VERSION ""

NS_ :

BS_:

BU_: XXX

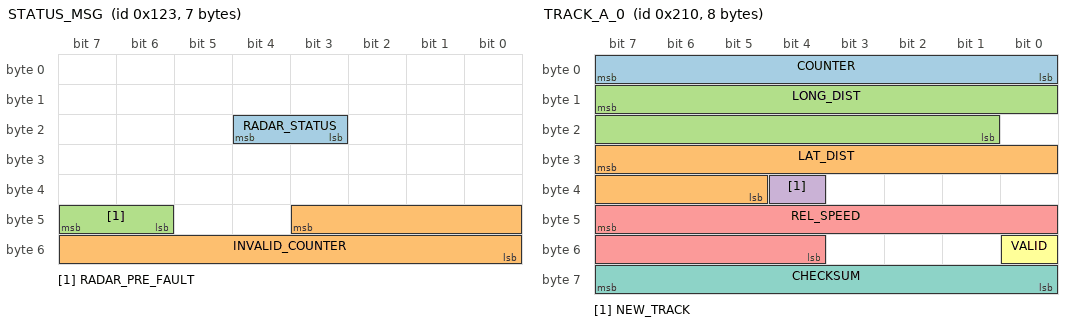
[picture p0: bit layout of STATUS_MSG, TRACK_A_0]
BO_ 291 STATUS_MSG: 7 XXX
 SG_ RADAR_STATUS : 20|2@0+ (1,0) [0|3] "" XXX
 SG_ INVALID_COUNTER : 43|12@0+ (1,0) [0|4095] "" XXX
 SG_ RADAR_PRE_FAULT : 47|2@0+ (1,0) [0|3] "" XXX

BO_ 528 TRACK_A_0: 8 XXX
 SG_ COUNTER : 7|8@0+ (1,0) [0|255] "" XXX
 SG_ LAT_DIST : 31|11@0- (0.04,0) [-50|50] "m" XXX
 SG_ LONG_DIST : 15|15@0+ (0.01,0) [0|300] "m" XXX
 SG_ NEW_TRACK : 36|1@0+ (1,0) [0|1] "" XXX
 SG_ REL_SPEED : 47|12@0- (0.025,0) [-100|100] "m/s" XXX
 SG_ VALID : 48|1@0+ (1,0) [0|1] "" XXX
 SG_ CHECKSUM : 63|8@0+ (1,0) [0|255] "" XXX

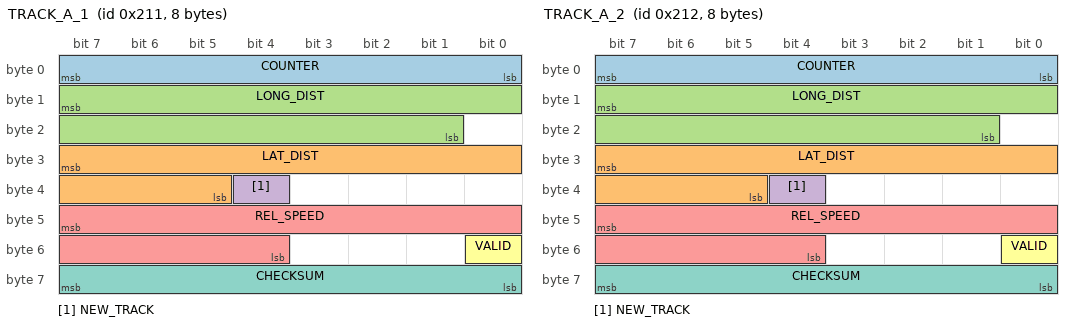
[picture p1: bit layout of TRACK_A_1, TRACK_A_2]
BO_ 529 TRACK_A_1: 8 XXX
 SG_ COUNTER : 7|8@0+ (1,0) [0|255] "" XXX
 SG_ LAT_DIST : 31|11@0- (0.04,0) [-50|50] "m" XXX
 SG_ LONG_DIST : 15|15@0+ (0.01,0) [0|300] "m" XXX
 SG_ NEW_TRACK : 36|1@0+ (1,0) [0|1] "" XXX
 SG_ REL_SPEED : 47|12@0- (0.025,0) [-100|100] "m/s" XXX
 SG_ VALID : 48|1@0+ (1,0) [0|1] "" XXX
 SG_ CHECKSUM : 63|8@0+ (1,0) [0|255] "" XXX

BO_ 530 TRACK_A_2: 8 XXX
 SG_ COUNTER : 7|8@0+ (1,0) [0|255] "" XXX
 SG_ LAT_DIST : 31|11@0- (0.04,0) [-50|50] "m" XXX
 SG_ LONG_DIST : 15|15@0+ (0.01,0) [0|300] "m" XXX
 SG_ NEW_TRACK : 36|1@0+ (1,0) [0|1] "" XXX
 SG_ REL_SPEED : 47|12@0- (0.025,0) [-100|100] "m/s" XXX
 SG_ VALID : 48|1@0+ (1,0) [0|1] "" XXX
 SG_ CHECKSUM : 63|8@0+ (1,0) [0|255] "" XXX

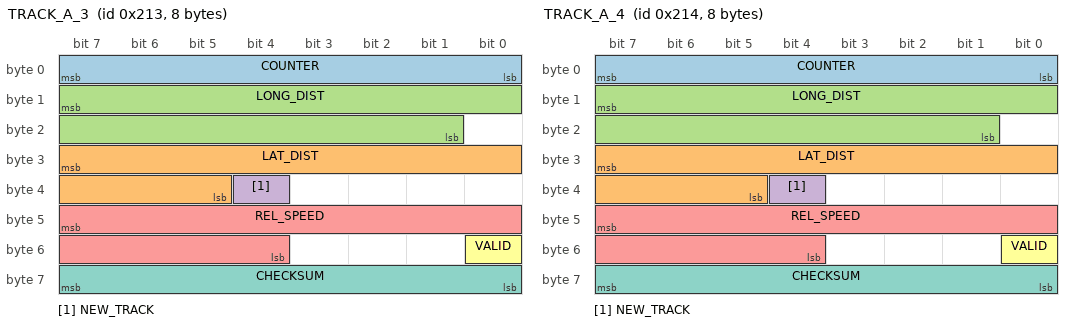
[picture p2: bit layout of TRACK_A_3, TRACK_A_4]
BO_ 531 TRACK_A_3: 8 XXX
 SG_ COUNTER : 7|8@0+ (1,0) [0|255] "" XXX
 SG_ LAT_DIST : 31|11@0- (0.04,0) [-50|50] "m" XXX
 SG_ LONG_DIST : 15|15@0+ (0.01,0) [0|300] "m" XXX
 SG_ NEW_TRACK : 36|1@0+ (1,0) [0|1] "" XXX
 SG_ REL_SPEED : 47|12@0- (0.025,0) [-100|100] "m/s" XXX
 SG_ VALID : 48|1@0+ (1,0) [0|1] "" XXX
 SG_ CHECKSUM : 63|8@0+ (1,0) [0|255] "" XXX

BO_ 532 TRACK_A_4: 8 XXX
 SG_ COUNTER : 7|8@0+ (1,0) [0|255] "" XXX
 SG_ LAT_DIST : 31|11@0- (0.04,0) [-50|50] "m" XXX
 SG_ LONG_DIST : 15|15@0+ (0.01,0) [0|300] "m" XXX
 SG_ NEW_TRACK : 36|1@0+ (1,0) [0|1] "" XXX
 SG_ REL_SPEED : 47|12@0- (0.025,0) [-100|100] "m/s" XXX
 SG_ VALID : 48|1@0+ (1,0) [0|1] "" XXX
 SG_ CHECKSUM : 63|8@0+ (1,0) [0|255] "" XXX

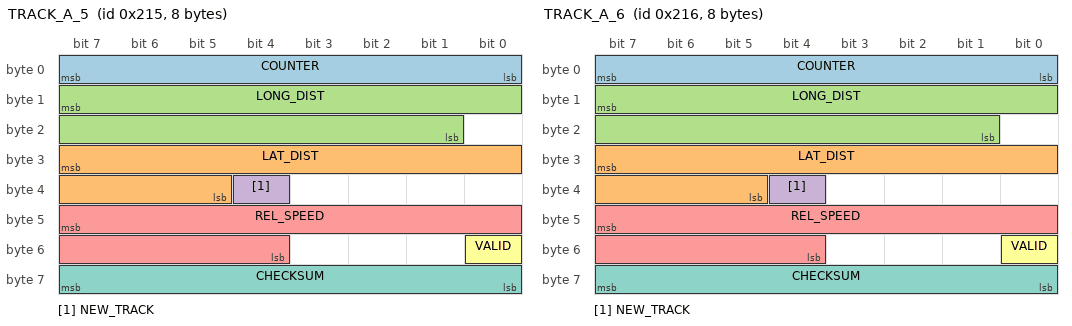
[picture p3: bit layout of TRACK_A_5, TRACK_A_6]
BO_ 533 TRACK_A_5: 8 XXX
 SG_ COUNTER : 7|8@0+ (1,0) [0|255] "" XXX
 SG_ LAT_DIST : 31|11@0- (0.04,0) [-50|50] "m" XXX
 SG_ LONG_DIST : 15|15@0+ (0.01,0) [0|300] "m" XXX
 SG_ NEW_TRACK : 36|1@0+ (1,0) [0|1] "" XXX
 SG_ REL_SPEED : 47|12@0- (0.025,0) [-100|100] "m/s" XXX
 SG_ VALID : 48|1@0+ (1,0) [0|1] "" XXX
 SG_ CHECKSUM : 63|8@0+ (1,0) [0|255] "" XXX

BO_ 534 TRACK_A_6: 8 XXX
 SG_ COUNTER : 7|8@0+ (1,0) [0|255] "" XXX
 SG_ LAT_DIST : 31|11@0- (0.04,0) [-50|50] "m" XXX
 SG_ LONG_DIST : 15|15@0+ (0.01,0) [0|300] "m" XXX
 SG_ NEW_TRACK : 36|1@0+ (1,0) [0|1] "" XXX
 SG_ REL_SPEED : 47|12@0- (0.025,0) [-100|100] "m/s" XXX
 SG_ VALID : 48|1@0+ (1,0) [0|1] "" XXX
 SG_ CHECKSUM : 63|8@0+ (1,0) [0|255] "" XXX

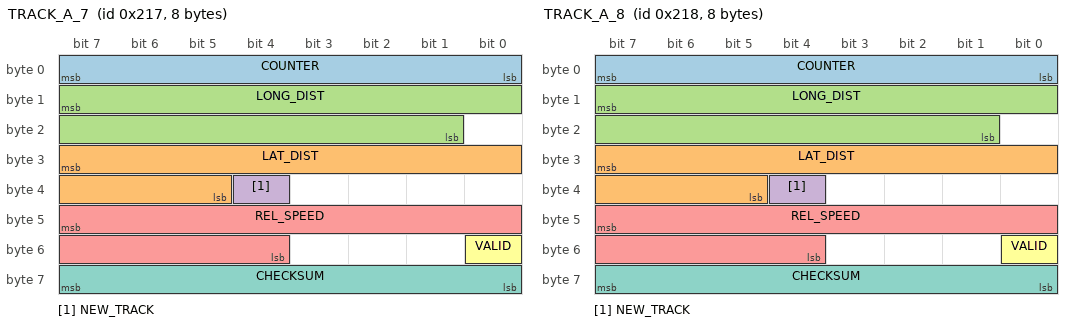
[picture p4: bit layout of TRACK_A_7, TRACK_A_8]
BO_ 535 TRACK_A_7: 8 XXX
 SG_ COUNTER : 7|8@0+ (1,0) [0|255] "" XXX
 SG_ LAT_DIST : 31|11@0- (0.04,0) [-50|50] "m" XXX
 SG_ LONG_DIST : 15|15@0+ (0.01,0) [0|300] "m" XXX
 SG_ NEW_TRACK : 36|1@0+ (1,0) [0|1] "" XXX
 SG_ REL_SPEED : 47|12@0- (0.025,0) [-100|100] "m/s" XXX
 SG_ VALID : 48|1@0+ (1,0) [0|1] "" XXX
 SG_ CHECKSUM : 63|8@0+ (1,0) [0|255] "" XXX

BO_ 536 TRACK_A_8: 8 XXX
 SG_ COUNTER : 7|8@0+ (1,0) [0|255] "" XXX
 SG_ LAT_DIST : 31|11@0- (0.04,0) [-50|50] "m" XXX
 SG_ LONG_DIST : 15|15@0+ (0.01,0) [0|300] "m" XXX
 SG_ NEW_TRACK : 36|1@0+ (1,0) [0|1] "" XXX
 SG_ REL_SPEED : 47|12@0- (0.025,0) [-100|100] "m/s" XXX
 SG_ VALID : 48|1@0+ (1,0) [0|1] "" XXX
 SG_ CHECKSUM : 63|8@0+ (1,0) [0|255] "" XXX

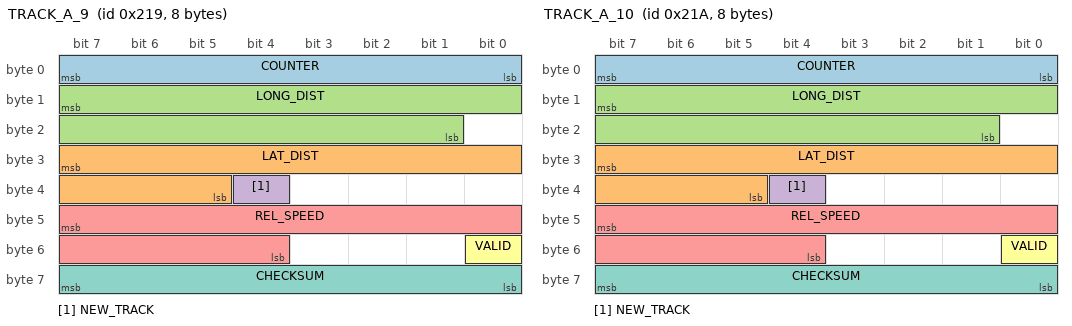
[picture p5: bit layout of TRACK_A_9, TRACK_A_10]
BO_ 537 TRACK_A_9: 8 XXX
 SG_ COUNTER : 7|8@0+ (1,0) [0|255] "" XXX
 SG_ LAT_DIST : 31|11@0- (0.04,0) [-50|50] "m" XXX
 SG_ LONG_DIST : 15|15@0+ (0.01,0) [0|300] "m" XXX
 SG_ NEW_TRACK : 36|1@0+ (1,0) [0|1] "" XXX
 SG_ REL_SPEED : 47|12@0- (0.025,0) [-100|100] "m/s" XXX
 SG_ VALID : 48|1@0+ (1,0) [0|1] "" XXX
 SG_ CHECKSUM : 63|8@0+ (1,0) [0|255] "" XXX

BO_ 538 TRACK_A_10: 8 XXX
 SG_ COUNTER : 7|8@0+ (1,0) [0|255] "" XXX
 SG_ LAT_DIST : 31|11@0- (0.04,0) [-50|50] "m" XXX
 SG_ LONG_DIST : 15|15@0+ (0.01,0) [0|300] "m" XXX
 SG_ NEW_TRACK : 36|1@0+ (1,0) [0|1] "" XXX
 SG_ REL_SPEED : 47|12@0- (0.025,0) [-100|100] "m/s" XXX
 SG_ VALID : 48|1@0+ (1,0) [0|1] "" XXX
 SG_ CHECKSUM : 63|8@0+ (1,0) [0|255] "" XXX

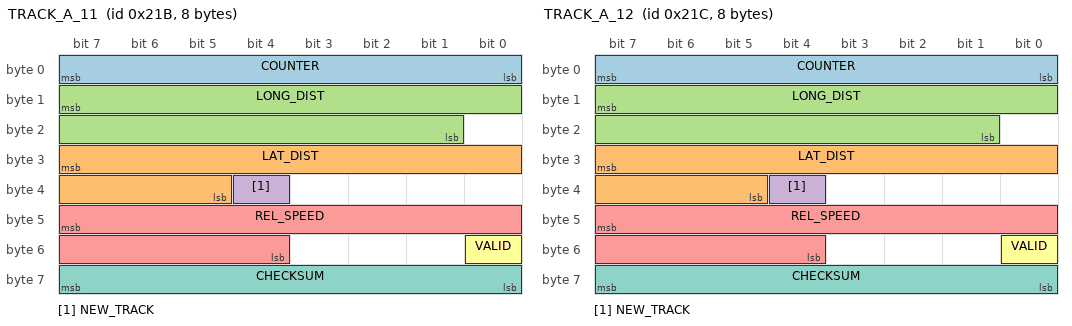
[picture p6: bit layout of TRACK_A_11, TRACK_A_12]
BO_ 539 TRACK_A_11: 8 XXX
 SG_ COUNTER : 7|8@0+ (1,0) [0|255] "" XXX
 SG_ LAT_DIST : 31|11@0- (0.04,0) [-50|50] "m" XXX
 SG_ LONG_DIST : 15|15@0+ (0.01,0) [0|300] "m" XXX
 SG_ NEW_TRACK : 36|1@0+ (1,0) [0|1] "" XXX
 SG_ REL_SPEED : 47|12@0- (0.025,0) [-100|100] "m/s" XXX
 SG_ VALID : 48|1@0+ (1,0) [0|1] "" XXX
 SG_ CHECKSUM : 63|8@0+ (1,0) [0|255] "" XXX

BO_ 540 TRACK_A_12: 8 XXX
 SG_ COUNTER : 7|8@0+ (1,0) [0|255] "" XXX
 SG_ LAT_DIST : 31|11@0- (0.04,0) [-50|50] "m" XXX
 SG_ LONG_DIST : 15|15@0+ (0.01,0) [0|300] "m" XXX
 SG_ NEW_TRACK : 36|1@0+ (1,0) [0|1] "" XXX
 SG_ REL_SPEED : 47|12@0- (0.025,0) [-100|100] "m/s" XXX
 SG_ VALID : 48|1@0+ (1,0) [0|1] "" XXX
 SG_ CHECKSUM : 63|8@0+ (1,0) [0|255] "" XXX

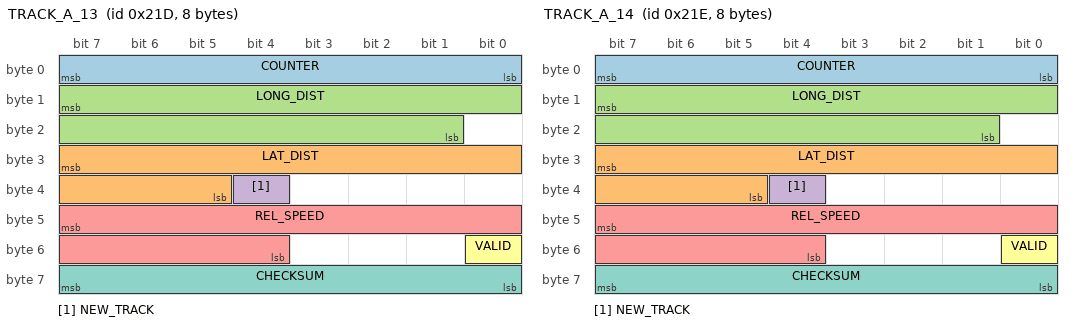
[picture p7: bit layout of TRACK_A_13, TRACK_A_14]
BO_ 541 TRACK_A_13: 8 XXX
 SG_ COUNTER : 7|8@0+ (1,0) [0|255] "" XXX
 SG_ LAT_DIST : 31|11@0- (0.04,0) [-50|50] "m" XXX
 SG_ LONG_DIST : 15|15@0+ (0.01,0) [0|300] "m" XXX
 SG_ NEW_TRACK : 36|1@0+ (1,0) [0|1] "" XXX
 SG_ REL_SPEED : 47|12@0- (0.025,0) [-100|100] "m/s" XXX
 SG_ VALID : 48|1@0+ (1,0) [0|1] "" XXX
 SG_ CHECKSUM : 63|8@0+ (1,0) [0|255] "" XXX

BO_ 542 TRACK_A_14: 8 XXX
 SG_ COUNTER : 7|8@0+ (1,0) [0|255] "" XXX
 SG_ LAT_DIST : 31|11@0- (0.04,0) [-50|50] "m" XXX
 SG_ LONG_DIST : 15|15@0+ (0.01,0) [0|300] "m" XXX
 SG_ NEW_TRACK : 36|1@0+ (1,0) [0|1] "" XXX
 SG_ REL_SPEED : 47|12@0- (0.025,0) [-100|100] "m/s" XXX
 SG_ VALID : 48|1@0+ (1,0) [0|1] "" XXX
 SG_ CHECKSUM : 63|8@0+ (1,0) [0|255] "" XXX

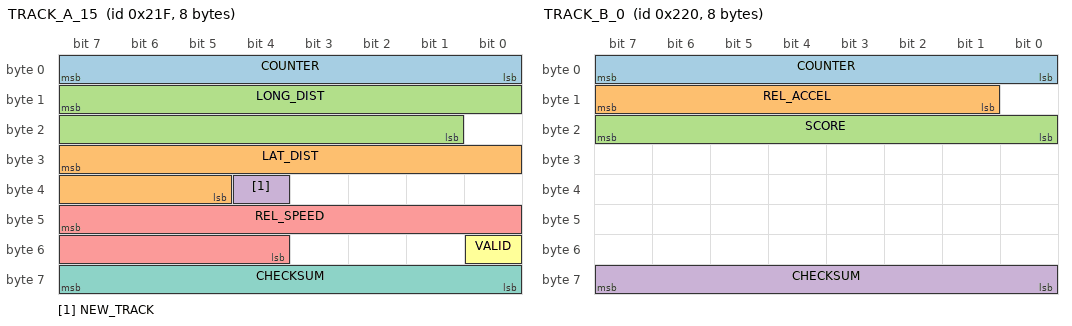
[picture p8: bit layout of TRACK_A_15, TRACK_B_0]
BO_ 543 TRACK_A_15: 8 XXX
 SG_ COUNTER : 7|8@0+ (1,0) [0|255] "" XXX
 SG_ LAT_DIST : 31|11@0- (0.04,0) [-50|50] "m" XXX
 SG_ LONG_DIST : 15|15@0+ (0.01,0) [0|300] "m" XXX
 SG_ NEW_TRACK : 36|1@0+ (1,0) [0|1] "" XXX
 SG_ REL_SPEED : 47|12@0- (0.025,0) [-100|100] "m/s" XXX
 SG_ VALID : 48|1@0+ (1,0) [0|1] "" XXX
 SG_ CHECKSUM : 63|8@0+ (1,0) [0|255] "" XXX

BO_ 544 TRACK_B_0: 8 XXX
 SG_ COUNTER : 7|8@0+ (1,0) [0|255] "" XXX
 SG_ REL_ACCEL : 15|7@0- (1,0) [-64|63] "" XXX
 SG_ SCORE : 23|8@0+ (1,0) [0|100] "" XXX
 SG_ CHECKSUM : 63|8@0+ (1,0) [0|255] "" XXX

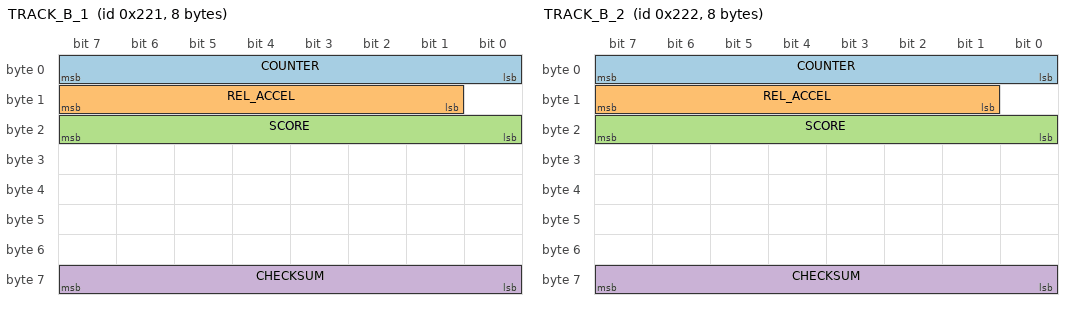
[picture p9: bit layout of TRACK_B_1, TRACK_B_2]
BO_ 545 TRACK_B_1: 8 XXX
 SG_ COUNTER : 7|8@0+ (1,0) [0|255] "" XXX
 SG_ REL_ACCEL : 15|7@0- (1,0) [-64|63] "" XXX
 SG_ SCORE : 23|8@0+ (1,0) [0|100] "" XXX
 SG_ CHECKSUM : 63|8@0+ (1,0) [0|255] "" XXX

BO_ 546 TRACK_B_2: 8 XXX
 SG_ COUNTER : 7|8@0+ (1,0) [0|255] "" XXX
 SG_ REL_ACCEL : 15|7@0- (1,0) [-64|63] "" XXX
 SG_ SCORE : 23|8@0+ (1,0) [0|100] "" XXX
 SG_ CHECKSUM : 63|8@0+ (1,0) [0|255] "" XXX

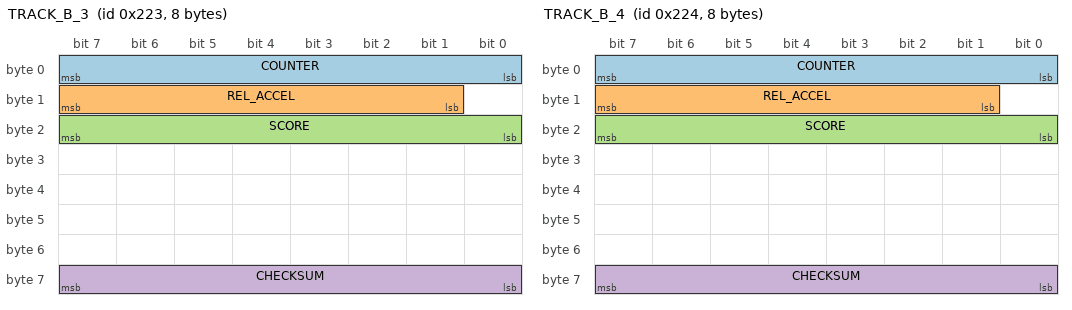
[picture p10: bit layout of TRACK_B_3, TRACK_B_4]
BO_ 547 TRACK_B_3: 8 XXX
 SG_ COUNTER : 7|8@0+ (1,0) [0|255] "" XXX
 SG_ REL_ACCEL : 15|7@0- (1,0) [-64|63] "" XXX
 SG_ SCORE : 23|8@0+ (1,0) [0|100] "" XXX
 SG_ CHECKSUM : 63|8@0+ (1,0) [0|255] "" XXX

BO_ 548 TRACK_B_4: 8 XXX
 SG_ COUNTER : 7|8@0+ (1,0) [0|255] "" XXX
 SG_ REL_ACCEL : 15|7@0- (1,0) [-64|63] "" XXX
 SG_ SCORE : 23|8@0+ (1,0) [0|100] "" XXX
 SG_ CHECKSUM : 63|8@0+ (1,0) [0|255] "" XXX

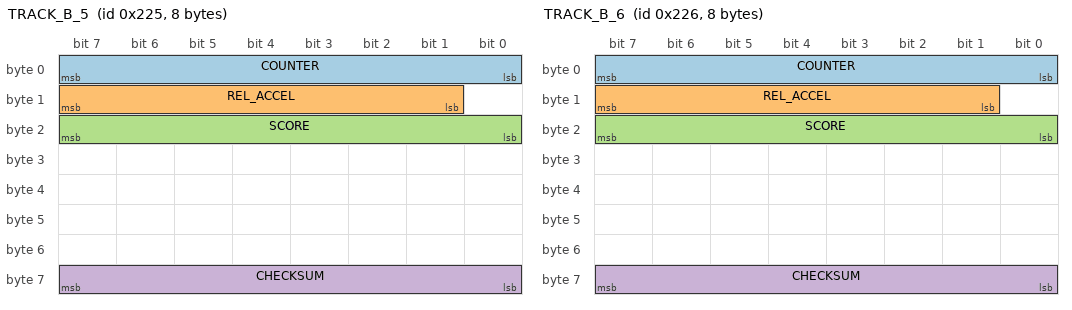
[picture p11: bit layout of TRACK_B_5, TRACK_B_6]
BO_ 549 TRACK_B_5: 8 XXX
 SG_ COUNTER : 7|8@0+ (1,0) [0|255] "" XXX
 SG_ REL_ACCEL : 15|7@0- (1,0) [-64|63] "" XXX
 SG_ SCORE : 23|8@0+ (1,0) [0|100] "" XXX
 SG_ CHECKSUM : 63|8@0+ (1,0) [0|255] "" XXX

BO_ 550 TRACK_B_6: 8 XXX
 SG_ COUNTER : 7|8@0+ (1,0) [0|255] "" XXX
 SG_ REL_ACCEL : 15|7@0- (1,0) [-64|63] "" XXX
 SG_ SCORE : 23|8@0+ (1,0) [0|100] "" XXX
 SG_ CHECKSUM : 63|8@0+ (1,0) [0|255] "" XXX

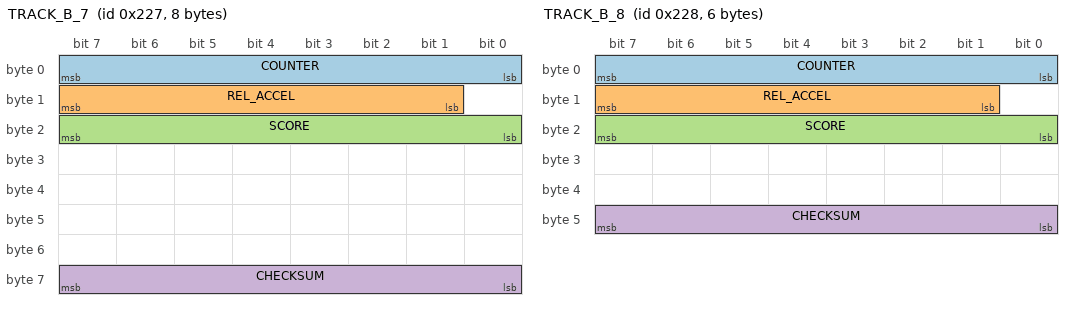
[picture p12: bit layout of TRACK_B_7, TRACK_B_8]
BO_ 551 TRACK_B_7: 8 XXX
 SG_ COUNTER : 7|8@0+ (1,0) [0|255] "" XXX
 SG_ REL_ACCEL : 15|7@0- (1,0) [-64|63] "" XXX
 SG_ SCORE : 23|8@0+ (1,0) [0|100] "" XXX
 SG_ CHECKSUM : 63|8@0+ (1,0) [0|255] "" XXX

BO_ 552 TRACK_B_8: 6 XXX
 SG_ COUNTER : 7|8@0+ (1,0) [0|255] "" XXX
 SG_ REL_ACCEL : 15|7@0- (1,0) [-64|63] "" XXX
 SG_ SCORE : 23|8@0+ (1,0) [0|100] "" XXX
 SG_ CHECKSUM : 47|8@0+ (1,0) [0|255] "" XXX

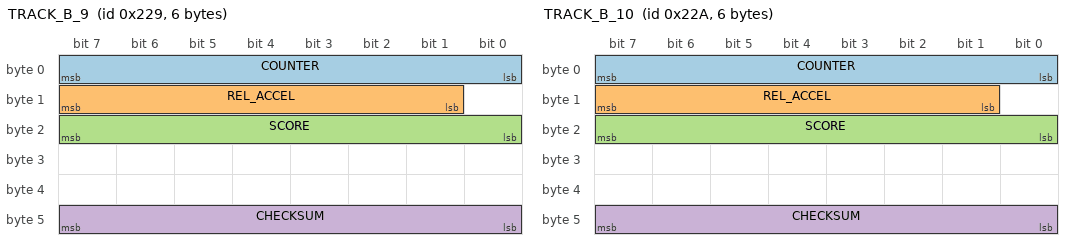
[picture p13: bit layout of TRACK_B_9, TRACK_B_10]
BO_ 553 TRACK_B_9: 6 XXX
 SG_ COUNTER : 7|8@0+ (1,0) [0|255] "" XXX
 SG_ REL_ACCEL : 15|7@0- (1,0) [-64|63] "" XXX
 SG_ SCORE : 23|8@0+ (1,0) [0|100] "" XXX
 SG_ CHECKSUM : 47|8@0+ (1,0) [0|255] "" XXX

BO_ 554 TRACK_B_10: 6 XXX
 SG_ COUNTER : 7|8@0+ (1,0) [0|255] "" XXX
 SG_ REL_ACCEL : 15|7@0- (1,0) [-64|63] "" XXX
 SG_ SCORE : 23|8@0+ (1,0) [0|100] "" XXX
 SG_ CHECKSUM : 47|8@0+ (1,0) [0|255] "" XXX

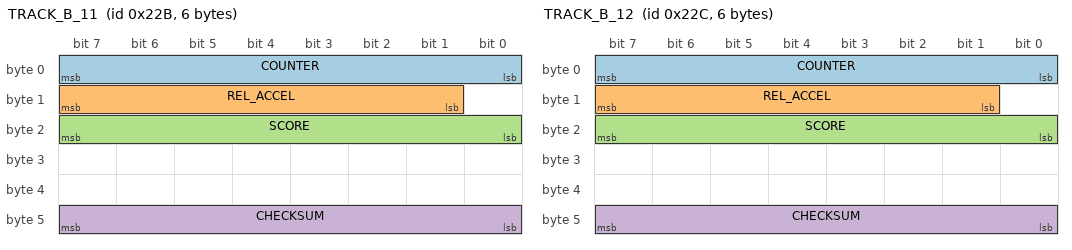
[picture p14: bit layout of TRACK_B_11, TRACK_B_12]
BO_ 555 TRACK_B_11: 6 XXX
 SG_ COUNTER : 7|8@0+ (1,0) [0|255] "" XXX
 SG_ REL_ACCEL : 15|7@0- (1,0) [-64|63] "" XXX
 SG_ SCORE : 23|8@0+ (1,0) [0|100] "" XXX
 SG_ CHECKSUM : 47|8@0+ (1,0) [0|255] "" XXX

BO_ 556 TRACK_B_12: 6 XXX
 SG_ COUNTER : 7|8@0+ (1,0) [0|255] "" XXX
 SG_ REL_ACCEL : 15|7@0- (1,0) [-64|63] "" XXX
 SG_ SCORE : 23|8@0+ (1,0) [0|100] "" XXX
 SG_ CHECKSUM : 47|8@0+ (1,0) [0|255] "" XXX

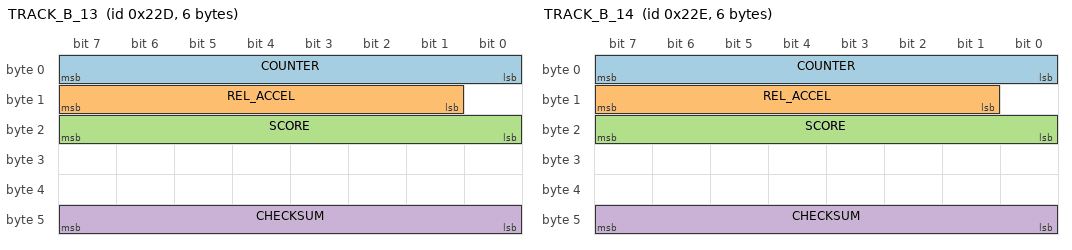
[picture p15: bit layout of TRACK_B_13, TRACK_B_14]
BO_ 557 TRACK_B_13: 6 XXX
 SG_ COUNTER : 7|8@0+ (1,0) [0|255] "" XXX
 SG_ REL_ACCEL : 15|7@0- (1,0) [-64|63] "" XXX
 SG_ SCORE : 23|8@0+ (1,0) [0|100] "" XXX
 SG_ CHECKSUM : 47|8@0+ (1,0) [0|255] "" XXX

BO_ 558 TRACK_B_14: 6 XXX
 SG_ COUNTER : 7|8@0+ (1,0) [0|255] "" XXX
 SG_ REL_ACCEL : 15|7@0- (1,0) [-64|63] "" XXX
 SG_ SCORE : 23|8@0+ (1,0) [0|100] "" XXX
 SG_ CHECKSUM : 47|8@0+ (1,0) [0|255] "" XXX

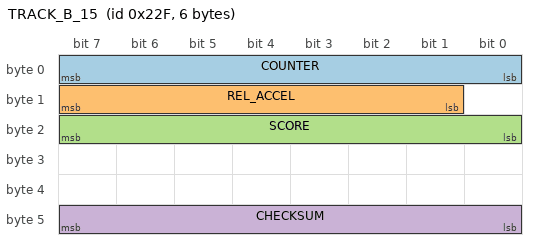
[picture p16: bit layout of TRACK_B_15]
BO_ 559 TRACK_B_15: 6 XXX
 SG_ COUNTER : 7|8@0+ (1,0) [0|255] "" XXX
 SG_ REL_ACCEL : 15|7@0- (1,0) [-64|63] "" XXX
 SG_ SCORE : 23|8@0+ (1,0) [0|100] "" XXX
 SG_ CHECKSUM : 47|8@0+ (1,0) [0|255] "" XXX

CM_ SG_ 291 RADAR_STATUS "Goes to 0 when radar is initializing, or car is at a standstill in non-US cars. Goes to 3 when INVALID_COUNTER is >= 2659 and throws dirty radar disable alert, or ACC is in non-adaptive mode.";
CM_ SG_ 291 INVALID_COUNTER "Unit unknown. Observed to rise when car is moving and radar is obstructed (object, snow, rain). Drops when obstruction is removed. Baseline is not the same across cars.";
CM_ SG_ 291 RADAR_PRE_FAULT "Goes to 3 when INVALID_COUNTER is >= 1358.";

VAL_ 291 RADAR_STATUS 0 "no points" 1 "ok" 3 "fault";
VAL_ 291 RADAR_PRE_FAULT 0 "ok" 3 "fault";
